# MKV10Z7 register map
Vendor: Freescale Semiconductor, Inc.; File version: 1.6
CPU: CM0PLUS r0p0, little endian, no MPU, no FPU, 0x2 interrupt priority bits, 0x0 interrupts
Registers are 32-bit, read-write, reset 0x0 unless marked. A register's access mark holds for its fields unless they carry their own. Offsets are from the block's base; [hi:lo] are bit positions; {n}, {i} and the like mark numbered series; 'fields as' and 'values as' point back to an identical list.

## MTB — Micro Trace Buffer
Base 0xF0000000; register names take the prefix MTB_
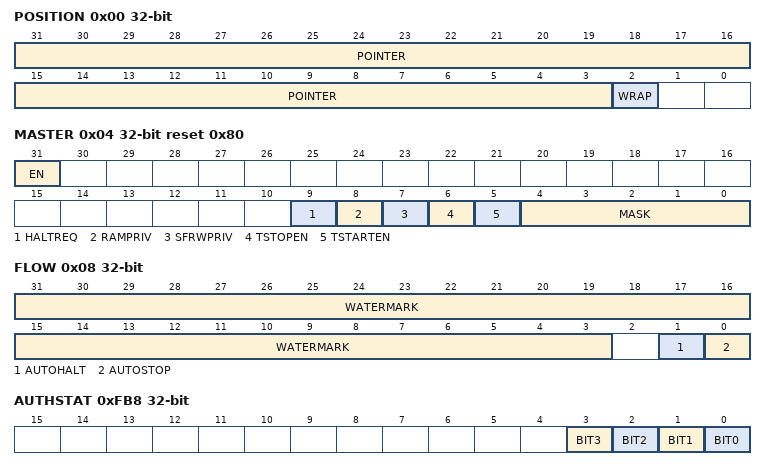
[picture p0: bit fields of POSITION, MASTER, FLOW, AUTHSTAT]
0x00 POSITION (reset mask 0x3) — MTB Position Register
  [31:3] POINTER — Trace Packet Address Pointer[28:0]
  [2] WRAP
0x04 MASTER reset 0x80 (reset mask 0xFFFFFFE0) — MTB Master Register
  [31] EN — Main Trace Enable
  [9] HALTREQ — Halt Request
  [8] RAMPRIV — RAM Privilege
  [7] SFRWPRIV — Special Function Register Write Privilege
  [6] TSTOPEN — Trace Stop Input Enable
  [5] TSTARTEN — Trace Start Input Enable
  [4:0] MASK
0x08 FLOW (reset mask 0x4) — MTB Flow Register
  [31:3] WATERMARK — WATERMARK[28:0]
  [1] AUTOHALT
  [0] AUTOSTOP
0x0C BASE ro reset not defined — MTB Base Register
  [31:0] BASEADDR
0xF00 MODECTRL ro — Integration Mode Control Register
0xFA0 TAGSET ro — Claim TAG Set Register
0xFA4 TAGCLEAR ro — Claim TAG Clear Register
0xFB0 LOCKACCESS ro
  [31:0] LOCKACCESS — Hardwired to 0x0000_0000
0xFB4 LOCKSTAT ro — Lock Status Register
0xFB8 AUTHSTAT ro — Authentication Status Register
  [3] BIT3
  [2] BIT2
  [1] BIT1
  [0] BIT0 — Connected to DBGEN.
0xFBC DEVICEARCH ro reset 0x47700A31 — Device Architecture Register
0xFC8 DEVICECFG ro — Device Configuration Register
0xFCC DEVICETYPID ro reset 0x31 — Device Type Identifier Register
{0xFC0+4i} PERIPHID{i} ro reset not defined (i=4..7) — Peripheral ID Register
  [31:0] PERIPHID
{0xFE0+4i} PERIPHID{i} ro reset not defined (i=0..3) — Peripheral ID Register
  [31:0] PERIPHID
{0xFF0+4i} COMPID{i} ro reset not defined (i=0..3) — Component ID Register
  [31:0] COMPID — Component ID

## ROM — System ROM
Base 0xF0002000; register names take the prefix ROM_
Registers as MTB, without POSITION, MASTER, FLOW, BASE, MODECTRL, TAGSET, TAGCLEAR, LOCKACCESS, LOCKSTAT, AUTHSTAT, DEVICEARCH, DEVICECFG, DEVICETYPID; these are added or differ:
{0x0+4i} ENTRY{i} ro reset not defined (i=0..2) — Entry
  [31:0] ENTRY
0x0C TABLEMARK ro — End of Table Marker Register
  [31:0] MARK
0xFCC SYSACCESS ro reset 0x1 — System Access Register

## MTBDWT — MTB data watchpoint and trace
Base 0xF0001000; register names take the prefix MTBDWT_
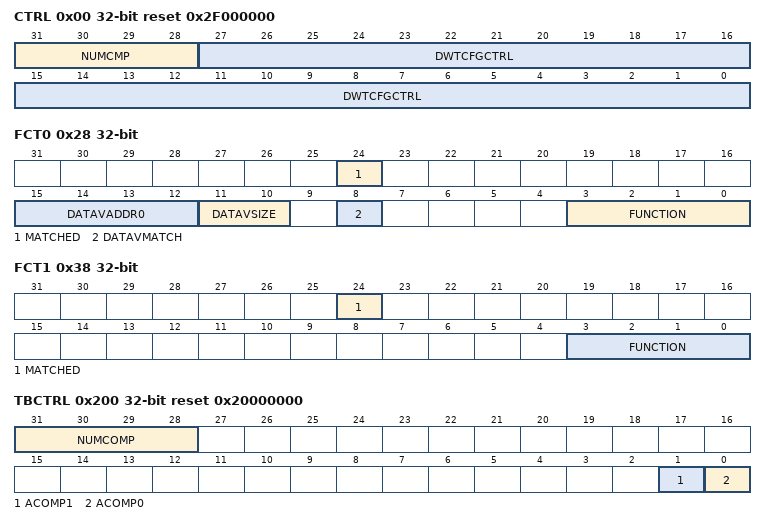
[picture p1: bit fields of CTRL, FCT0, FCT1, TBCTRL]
0x00 CTRL ro reset 0x2F000000 — MTB DWT Control Register
  [31:28] NUMCMP — Number of comparators
  [27:0] DWTCFGCTRL — DWT configuration controls
0x20 COMP0 — MTB_DWT Comparator Register
  [31:0] COMP — Reference value for comparison
0x24 MASK0 — MTB_DWT Comparator Mask Register
  [4:0] MASK
0x28 FCT0 — MTB_DWT Comparator Function Register 0
  [24] MATCHED ro — Comparator match
    0=No match; 1=Match occurred
  [15:12] DATAVADDR0 — Data Value Address 0
  [11:10] DATAVSIZE — Data Value Size
    0=Byte; 1=Halfword; 2=Word; 3=Reserved. Any attempts to use this value results in UNPREDICTABLE behavior.
  [8] DATAVMATCH — Data Value Match
    0=Perform address comparison; 1=Perform data value comparison
  [3:0] FUNCTION
    0=Disabled; 4=Instruction fetch; 5=Data operand read; 6=Data operand write; 7=Data operand (read + write)
0x30 COMP1 — MTB_DWT Comparator Register
  [31:0] COMP — Reference value for comparison
0x34 MASK1 — MTB_DWT Comparator Mask Register
  [4:0] MASK
0x38 FCT1 — MTB_DWT Comparator Function Register 1
  [24] MATCHED ro — Comparator match
    0=No match; 1=Match occurred
  [3:0] FUNCTION
    values as FCT0.FUNCTION
0x200 TBCTRL reset 0x20000000 — MTB_DWT Trace Buffer Control Register
  [31:28] NUMCOMP ro — Number of Comparators
  [1] ACOMP1 — Action based on Comparator 1 match
    0=Trigger TSTOP based on the assertion of MTBDWT_FCT1[MATCHED]; 1=Trigger TSTART based on the assertion of MTBDWT_FCT1[MATCHED]
  [0] ACOMP0 — Action based on Comparator 0 match
    0=Trigger TSTOP based on the assertion of MTBDWT_FCT0[MATCHED]; 1=Trigger TSTART based on the assertion of MTBDWT_FCT0[MATCHED]
0xFC8 DEVICECFG ro — Device Configuration Register
0xFCC DEVICETYPID ro reset 0x4 — Device Type Identifier Register
{0xFC0+4i} PERIPHID{i} ro reset not defined (i=4..7) — Peripheral ID Register
  [31:0] PERIPHID
{0xFE0+4i} PERIPHID{i} ro reset not defined (i=0..3) — Peripheral ID Register
  [31:0] PERIPHID
{0xFF0+4i} COMPID{i} ro reset not defined (i=0..3) — Component ID Register
  [31:0] COMPID — Component ID
